VERSION ""

NS_ :

BS_:

BU_: EON XXX RDC SZL VGSG JBBF RFK FLA RAD1 CAS CID AHM HKL HUD EKP DWA DSC SM_BF GWS VDM DDE1 ACI CCC DSC SM_FA CTM LDM RSE MRSZ VDA EDCK ZBE EGS ACC_Sensor Kombi IHKA ARS ACSM FZD PGS NVC AFS DME FRMFA EMF FKA VSW EPS PDC DKG EHC Diagnosetool_PT_CAN Diagnosetool_K_CAN_System Vector__XXX

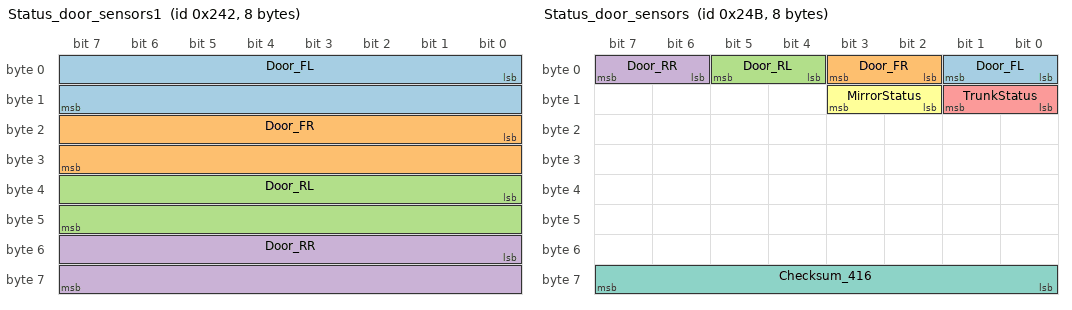
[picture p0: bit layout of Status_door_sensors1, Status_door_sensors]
BO_ 578 Status_door_sensors1: 8 DBC
  SG_ Door_FL : 0|16@1- (1,0) [0|1] "" XXX
  SG_ Door_FR : 16|16@1- (1,0) [0|1] "" XXX
  SG_ Door_RL : 32|16@1- (1,0) [0|1] "" XXX
  SG_ Door_RR : 48|16@1- (1,0) [0|1] "" XXX

BO_ 587 Status_door_sensors: 8 DBC
  SG_ Door_FL : 0|2@1+ (1.0,0.0) [0.0|3.0] ""  CLU
  SG_ Door_FR : 2|2@1+ (1.0,0.0) [0.0|3.0] ""  CLU
  SG_ Door_RL : 4|2@1+ (1.0,0.0) [0.0|3.0] ""  CLU
  SG_ Door_RR : 6|2@1+ (1.0,0.0) [0.0|3.0] ""  CLU
  SG_ TrunkStatus: 8|2@1+ (1.0,0.0) [0.0|3.0] ""  CLU
  SG_ MirrorStatus : 10|2@1+ (1.0,0.0) [0.0|3.0] ""  CLU
  SG_ Checksum_416 : 56|8@1+ (1,0) [0|15] "" XXX

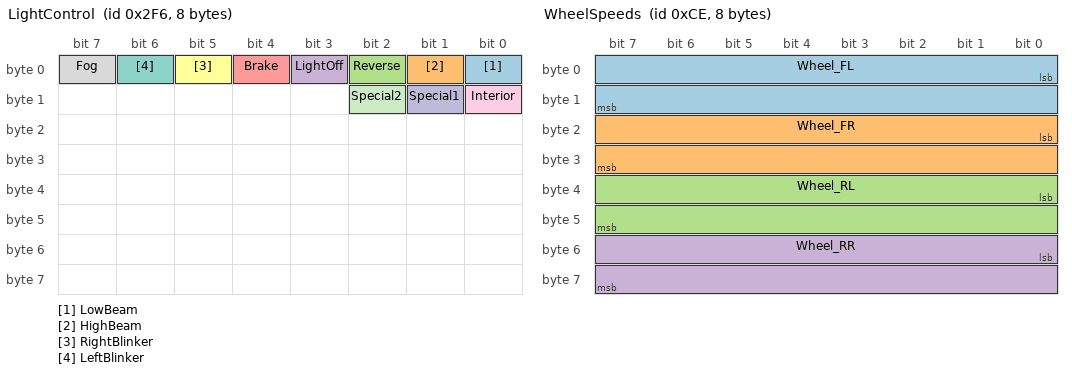
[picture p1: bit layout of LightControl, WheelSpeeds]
BO_ 758 LightControl: 8 FRMFA
  SG_ LowBeam : 0|1@1+ (1,0) [0|1] ""  BDC
  SG_ HighBeam : 1|1@1+ (1,0) [0|1] ""  BDC
  SG_ Reverse : 2|1@1+ (1,0) [0|1] ""  BDC
  SG_ LightOff : 3|1@1+ (1,0) [0|1] ""  BDC
  SG_ Brake : 4|1@1+ (1,0) [0|1] ""  BDC
  SG_ RightBlinker : 5|1@1+ (1,0) [0|1] ""  BDC
  SG_ LeftBlinker : 6|1@1+ (1,0) [0|1] ""  BDC
  SG_ Fog : 7|1@1+ (1,0) [0|1] ""  BDC
  SG_ Interior : 8|1@1+ (1,0) [0|1] ""  BDC
  SG_ Special1 : 9|1@1+ (1,0) [0|1] ""  BDC
  SG_ Special2 : 10|1@1+ (1,0) [0|1] ""  BDC

BO_ 206 WheelSpeeds: 8 DSC
  SG_ Wheel_FL : 0|16@1- (0.0625,0) [0|255] "kph" XXX
  SG_ Wheel_FR : 16|16@1- (0.0625,0) [0|255] "kph" XXX
  SG_ Wheel_RL : 32|16@1- (0.0625,0) [0|255] "kph" XXX
  SG_ Wheel_RR : 48|16@1- (0.0625,0) [0|255] "kph" XXX

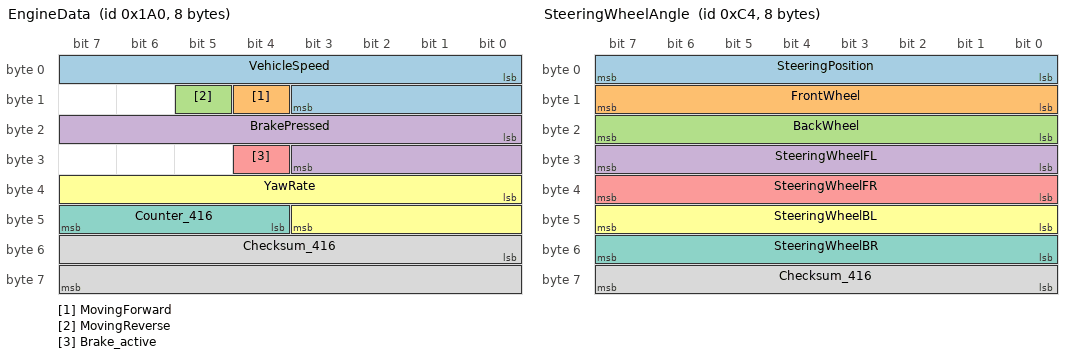
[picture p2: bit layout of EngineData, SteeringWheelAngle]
BO_ 416 EngineData: 8 DSC
  SG_ VehicleSpeed : 0|12@1- (1,0) [0|255] "kph" XXX
  SG_ MovingForward : 12|1@1+ (1,0) [0|1] "" XXX
  SG_ MovingReverse : 13|1@1+ (1,0) [0|1] "" XXX
  SG_ BrakePressed : 16|12@1+ (0.01,0) [0|100] "" XXX
  SG_ Brake_active : 28|1@1+ (1,0) [0|1] "" XXX
  SG_ YawRate : 32|12@1- (1,0) [0|255] "" XXX
  SG_ Counter_416 : 44|4@1+ (1,0) [0|14] "" XXX
  SG_ Checksum_416 : 48|16@1+ (1,0) [0|15] "" XXX

BO_ 436 InstrumentHandBrake: 8 CCC
  SG_ HandbrakeActive : 41|1@1+ (1,0) [0|1] "" XXX
  SG_ Checksum_416 : 56|8@1+ (1,0) [0|15] "" XXX

BO_ 196 SteeringWheelAngle: 8 DSC
  SG_ SteeringPosition : 0|8@1- (0.01,0) [-1.28|1.27] "" XXX
  SG_ FrontWheel : 8|8@1- (1.0,0) [-128|127] "degree" XXX
  SG_ BackWheel : 16|8@1- (1.0,0) [-128|127] "degree" XXX
  SG_ SteeringWheelFL : 24|8@1- (1.0,0) [-128|127] "degree" XXX
  SG_ SteeringWheelFR : 32|8@1- (1.0,0) [-128|127] "degree" XXX
  SG_ SteeringWheelBL : 40|8@1- (1.0,0) [-128|127] "degree" XXX
  SG_ SteeringWheelBR : 48|8@1- (1.0,0) [-128|127] "degree" XXX
  SG_ Checksum_416 : 56|8@1+ (1.0,0) [0|255] "" XXX

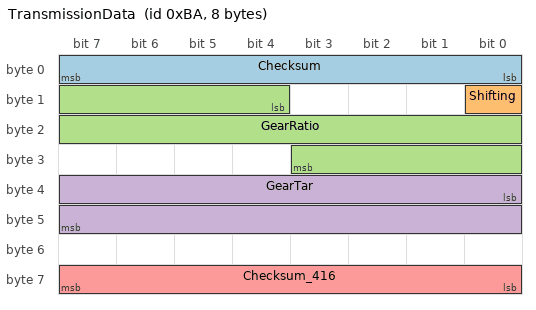
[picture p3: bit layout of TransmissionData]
BO_ 186 TransmissionData: 8 EGS
  SG_ Checksum : 0|8@1+ (1,0) [0|65535] "" XXX
  SG_ Shifting : 8|1@1+ (1,0) [0|1] "" XXX
  SG_ GearRatio : 12|16@1+ (0.05,0) [0|255] "" XXX
  SG_ GearTar : 32|16@1- (1,0) [-1|127] "" XXX
  SG_ Checksum_416 : 56|8@1+ (1,0) [0|15] "" XXX

BO_ 187 TransmissionDataTest: 8 EGS
  SG_ GearTar : 0|16@1- (1,0) [-1|127] "" XXX
